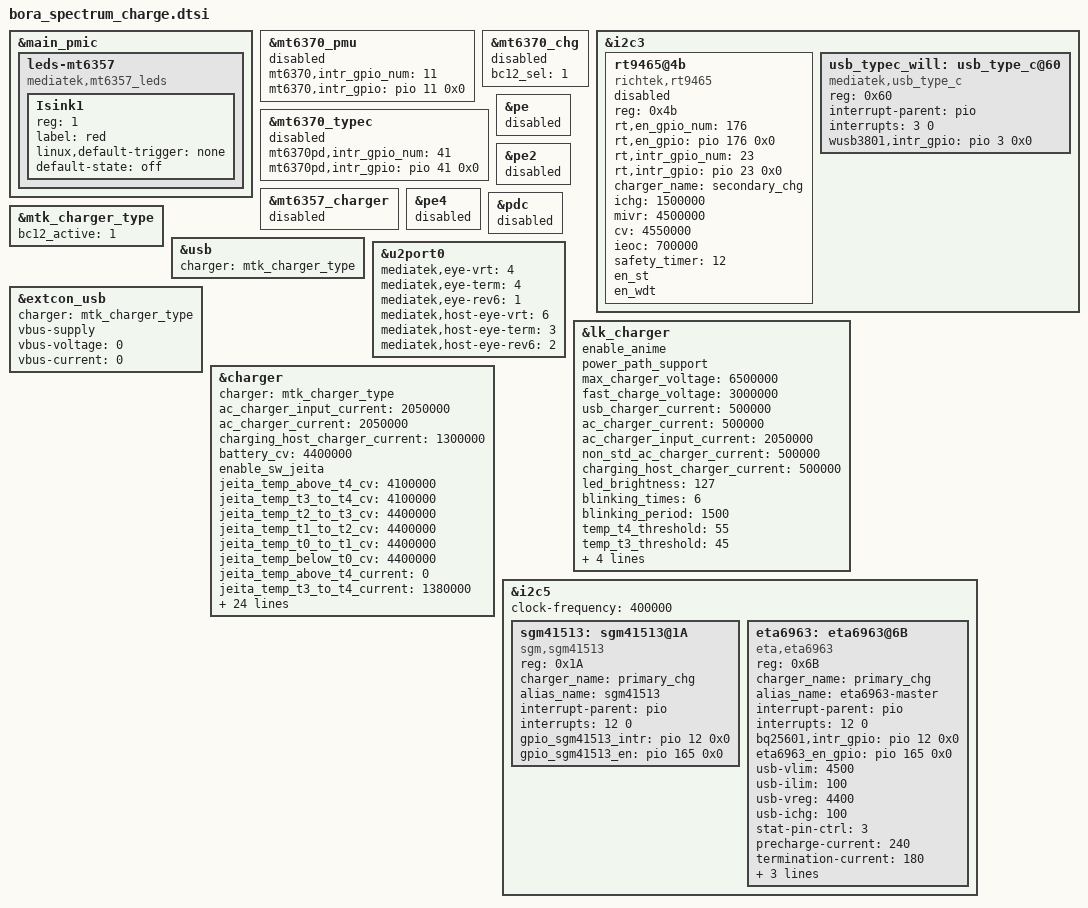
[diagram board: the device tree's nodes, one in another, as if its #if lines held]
// SPDX-License-Identifier: GPL-2.0+
&main_pmic {
	leds-mt6357 {
		compatible = "mediatek,mt6357_leds";
		Isink1 {
			reg = <1>;
			label = "red";
			linux,default-trigger = "none";
			default-state = "off";
		};
	};
};

&mt6370_pmu {
	mt6370,intr_gpio_num = <11>; /* direct defined GPIO num */
	mt6370,intr_gpio = <&pio 11 0x0>;
	status = "disabled";
};

&mt6370_chg {
	bc12_sel = <1>;
	status = "disabled";
};

&i2c3 {
	rt9465@4b {
		compatible = "richtek,rt9465";
		reg = <0x4b>;
		status = "disabled";
		rt,en_gpio_num = <176>;
		rt,en_gpio = <&pio 176 0x0>;
		rt,intr_gpio_num = <23>; /* direct defined GPIO num */
		rt,intr_gpio = <&pio 23 0x0>;
		interrupt-names = "wdtmri";
		charger_name = "secondary_chg";
		ichg = <1500000>; /* uA */
		mivr = <4500000>; /* uV */
		cv = <4550000>; /* uV */
		ieoc = <700000>; /* uA */
		safety_timer = <12>; /* hour */
		en_st; /* safety timer */
		/* en_te; */
		en_wdt;
	};
};

&mt6370_typec {
	mt6370pd,intr_gpio_num = <41>; /* direct defined GPIO num */
	mt6370pd,intr_gpio = <&pio 41 0x0>;
	status = "disabled";
};

&mt6357_charger {
	status = "disabled";
};

&pe {
	status = "disabled";
};

&pe2 {
	status = "disabled";
};

&pe4 {
	status = "disabled";
};

&pdc {
	status = "disabled";
};

&mtk_charger_type {
	bc12_active = <1>;
};

&usb {
	charger = <&mtk_charger_type>;
};

&u2port0 {
	mediatek,eye-vrt = <4>;
	mediatek,eye-term = <4>;
	mediatek,eye-rev6 = <1>; /* 0~3 */
	mediatek,host-eye-vrt = <6>; /* 0~7 */
	mediatek,host-eye-term = <3>; /* 0~7 */
	mediatek,host-eye-rev6 = <2>; /* 0~3 */
};

&extcon_usb {
	charger = <&mtk_charger_type>;
	vbus-supply;
	vbus-voltage = <0>;
	vbus-current = <0>;
};

&lk_charger {
	enable_anime;
	power_path_support;
	max_charger_voltage = <6500000>;
	fast_charge_voltage = <3000000>;

	/* charging current */
	usb_charger_current = <500000>;
	ac_charger_current = <500000>;
	ac_charger_input_current = <2050000>;
	non_std_ac_charger_current = <500000>;
	charging_host_charger_current = <500000>;

	led_brightness = <127>;
	blinking_times = <6>;
	blinking_period = <1500>;
	temp_t4_threshold = <55>;
	temp_t3_threshold = <45>;
	temp_t1_threshold = <6>;
	temp_t0_threshold = <1>;
	i2c_id = <5>;
	chr_ce_gpio = <165>;
};

&charger {
	charger = <&mtk_charger_type>;
	/delete-property/enable_min_charge_temp;
	/delete-property/enable_dynamic_mivr;
	ac_charger_input_current = <2050000>;
	ac_charger_current = <2050000>;
	charging_host_charger_current = <1300000>;
	battery_cv = <4400000>;
	enable_sw_jeita;
	/* sw jeita */
	jeita_temp_above_t4_cv = <4100000>;
	jeita_temp_t3_to_t4_cv = <4100000>;
	jeita_temp_t2_to_t3_cv = <4400000>;
	jeita_temp_t1_to_t2_cv = <4400000>;
	jeita_temp_t0_to_t1_cv = <4400000>;
	jeita_temp_below_t0_cv = <4400000>;
	jeita_temp_above_t4_current = <0>;
	jeita_temp_t3_to_t4_current = <1380000>;
	jeita_temp_t2_to_t3_current = <2050000>;
	jeita_temp_t1_to_t2_current = <840000>;
	jeita_temp_t0_to_t1_current = <840000>;
	jeita_temp_below_t0_current = <0>;

#if defined(TARGET_BUILD_IEEE1725)
	temp_t4_thres = <53>;
#else
	temp_t4_thres = <55>;
#endif
	temp_t4_thres_minus_x_degree = <51>;
	temp_t3_thres = <42>;
	temp_t3_thres_minus_x_degree = <43>;
	temp_t2_thres = <11>;
	temp_t2_thres_plus_x_degree = <10>;
	temp_t1_thres = <6>;
	temp_t1_thres_plus_x_degree = <5>;
#if defined(TARGET_BUILD_IEEE1725)
	temp_t0_thres = <2>;
	temp_t0_thres_plus_x_degree = <1>;
	temp_neg_10_thres = <2>;
#else
	temp_t0_thres = <1>;
	temp_t0_thres_plus_x_degree = <0>;
	temp_neg_10_thres = <1>;
#endif

	enable_min_charge_temp;
	min_charge_temp = <1>;
#if defined(TARGET_BUILD_IEEE1725)
	min_charge_temp_plus_x_degree = <2>;
	max_charge_temp = <53>;
#else
	min_charge_temp_plus_x_degree = <1>;
	max_charge_temp = <55>;
#endif
	max_charge_temp_minus_x_degree = <51>;

	enable_step_chg;
	step_chg_vbat = <4290000>;
	step_chg_vbat_hysteresis = <70000>;
	setp_chg_current = <1960000>;
};

&i2c3 {
	usb_typec_will:usb_type_c@60 {
		compatible = "mediatek,usb_type_c";
		reg = <0x60>;
		interrupt-parent = <&pio>;
		interrupts = <3 0>;
		wusb3801,intr_gpio = <&pio 3 0x0>;
		interrupt-names = "wusb3801_int_irq";
		status = "okay";
	};
};

&i2c5 {
	#address-cells = <1>;
	#size-cells = <0>;
	clock-frequency = <400000>;
	status = "okay";
	sgm41513:sgm41513@1A {
		compatible = "sgm,sgm41513";
		reg = <0x1A>;
		charger_name = "primary_chg";
		alias_name = "sgm41513";
		interrupt-parent = <&pio>;
		interrupts = <12 0>;
		gpio_sgm41513_intr = <&pio 12 0x0>;
		gpio_sgm41513_en = <&pio 165 0x0>;
		status = "okay";
	};
	eta6963:eta6963@6B {
		compatible = "eta,eta6963";
		reg = <0x6B>;
		charger_name = "primary_chg";
		alias_name = "eta6963-master";
		interrupt-parent = <&pio>;
		interrupts = <12 0>;
		bq25601,intr_gpio = <&pio 12 0x0>;
		eta6963_en_gpio = <&pio 165 0x0>;
		usb-vlim = <4500>;
		usb-ilim = <100>;
		usb-vreg = <4400>;
		usb-ichg = <100>;
		stat-pin-ctrl = <3>;
		precharge-current = <240>;
		termination-current = <180>;
		boost-voltage = <5000>;
		boost-current = <1200>;
		vac-ovp-threshold = <6500>;
		status = "okay";
	};
};

